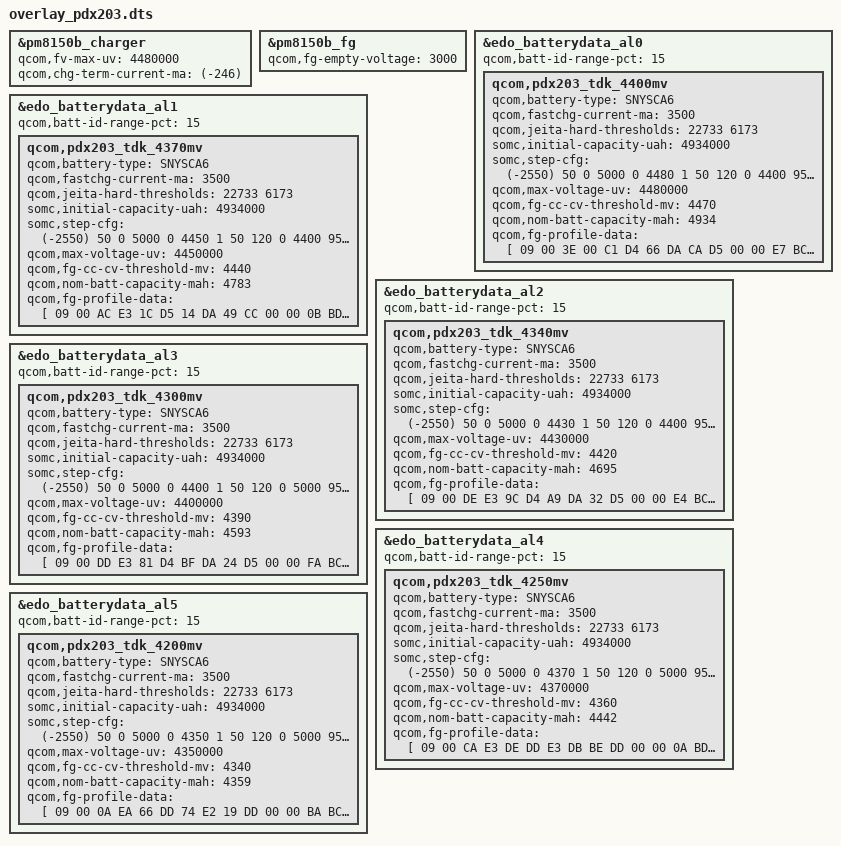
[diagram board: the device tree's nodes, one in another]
/dts-v1/;
/plugin/;

&pm8150b_charger {
	qcom,fv-max-uv = <4480000>;
	qcom,chg-term-current-ma = <(-246)>;
};
&pm8150b_fg {
	qcom,fg-empty-voltage = <3000>;
};
&edo_batterydata_al0 {
	qcom,batt-id-range-pct = <15>;
	qcom,pdx203_tdk_4400mv {
		qcom,battery-type = "SNYSCA6";
		qcom,fastchg-current-ma = <3500>;
		qcom,jeita-hard-thresholds = <22733 6173>;
		somc,initial-capacity-uah = <4934000>;
		somc,step-cfg = <
			(-2550)  50    0 5000    0 4480 1
			    50  120    0 4400  950 4480 2
			    50  120 4400 5000  700 4480 2
			   120  150    0 4150 2450 4480 3
			   120  150 4150 4250 1950 4480 3
			   120  150 4250 4350 1450 4480 3
			   120  150 4350 5000  950 4480 3
			   150  200    0 4150 2950 4480 3
			   150  200 4150 4250 2450 4480 3
			   150  200 4250 4350 1950 4480 3
			   150  200 4350 5000 1450 4480 3
			   200  350    0 4250 3500 4480 3
			   200  350 4250 4300 3500 4480 3
			   200  350 4300 4400 2450 4480 3
			   200  350 4400 5000 1700 4480 3
			   350  450    0 4250 3500 4480 3
			   350  450 4250 4300 3500 4480 3
			   350  450 4300 4400 2450 4480 3
			   350  450 4400 5000 1700 4480 3
			   450  550    0 5000 1450 4200 4
			   550 2550    0 5000    0 4200 5
		>;
		qcom,max-voltage-uv = <4480000>;
		qcom,fg-cc-cv-threshold-mv = <4470>;
		qcom,nom-batt-capacity-mah = <4934>;
		qcom,fg-profile-data = [
			 09 00 3E 00
			 C1 D4 66 DA
			 CA D5 00 00
			 E7 BC F7 8A
			 FB 87 94 8B
			 3F 9D 68 80
			 20 00 DB FA
			 48 13 D7 FD
			 0F E5 CE 07
			 32 00 5B 00
			 A3 ED 27 D3
			 84 0A 35 E5
			 49 C5 01 12
			 E3 01 A9 D2
			 60 00 4B 00
			 4C 00 48 00
			 28 00 2F 00
			 37 00 3C 00
			 40 00 41 00
			 40 00 60 00
			 35 00 41 00
			 48 00 44 00
			 3D 00 90 00
			 5F 64 4E 00
			 44 00 40 08
			 60 F8 4C 00
			 47 00 6C 10
			 55 10 48 00
			 99 28 69 48
			 56 60 4A 0C
			 48 00 D8 00
			 7B 1F BC 0D
			 2B 02 A7 05
			 80 1C 4A 0B
			 A3 0D 91 22
			 27 18 31 42
			 50 55 49 02
			 67 11 78 1F
			 CF 05 33 0A
			 AE 06 E2 1C
			 FC 01 B5 05
			 90 02 76 18
			 3F 23 0C 45
			 B1 53 77 11
			 4C 1F FD E5
			 1B C2 B8 96
			 DC 1C A2 B9
			 F2 04 8A BB
			 3A 18 48 93
			 16 85 8C 9B
			 80 98 09 80
			 BA EB BF 04
			 59 FC E2 03
			 00 00 83 DC
			 49 E2 F0 FF
			 23 BB 04 AD
			 18 10 19 F0
			 94 C5 93 03
			 17 05 9F 00
			 CE 07 32 00
			 6A 01 76 02
			 F8 05 1F 02
			 07 05 03 05
			 A0 03 86 02
			 14 04 44 00
			 3D 00 4C 00
			 50 64 54 00
			 52 00 52 08
			 54 F8 52 00
			 55 00 68 08
			 34 08 42 00
			 55 28 52 48
			 5E 58 6F 0D
			 48 00 59 00
			 5D 08 61 00
			 54 00 42 00
			 4B 08 56 08
			 4E 00 62 28
			 7A 48 46 60
			 59 0D 61 00
			 61 00 49 08
			 D8 F8 5D 20
			 57 05 52 0A
			 27 0D 09 1D
			 AB 22 A2 44
			 55 5B 94 18
			 11 02 A4 05
			 B7 03 78 0F
			 3F 0A 38 20
			 14 05 C2 02
			 1B 06 D9 1C
			 C7 02 55 04
			 E3 03 85 18
			 16 02 87 05
			 06 02 71 00
			 53 1F FF 05
			 2B 02 39 05
			 DB 1C 59 02
			 0F 05 4F 03
			 A7 18 67 03
			 9F 04 51 02
			 6D 00 0D 01
			 C0 00 FA 00
			 46 13 00 00
		];
	};
};
&edo_batterydata_al1 {
	qcom,batt-id-range-pct = <15>;
	qcom,pdx203_tdk_4370mv {
		qcom,battery-type = "SNYSCA6";
		qcom,fastchg-current-ma = <3500>;
		qcom,jeita-hard-thresholds = <22733 6173>;
		somc,initial-capacity-uah = <4934000>;
		somc,step-cfg = <
			(-2550)  50    0 5000    0 4450 1
			    50  120    0 4400  950 4450 2
			    50  120 4400 5000  700 4450 2
			   120  150    0 4150 2450 4450 3
			   120  150 4150 4250 1950 4450 3
			   120  150 4250 4350 1450 4450 3
			   120  150 4350 5000  950 4450 3
			   150  200    0 4150 2700 4450 3
			   150  200 4150 4250 2200 4450 3
			   150  200 4250 4350 1950 4450 3
			   150  200 4350 5000 1450 4450 3
			   200  350    0 4200 3500 4450 3
			   200  350 4200 4250 3400 4450 3
			   200  350 4250 4350 2200 4450 3
			   200  350 4350 5000 1450 4450 3
			   350  450    0 4200 3500 4450 3
			   350  450 4200 4250 3400 4450 3
			   350  450 4250 4350 2200 4450 3
			   350  450 4350 5000 1450 4450 3
			   450  550    0 5000 1450 4200 4
			   550 2550    0 5000    0 4200 5
		>;
		qcom,max-voltage-uv = <4450000>;
		qcom,fg-cc-cv-threshold-mv = <4440>;
		qcom,nom-batt-capacity-mah = <4783>;
		qcom,fg-profile-data = [
			 09 00 AC E3
			 1C D5 14 DA
			 49 CC 00 00
			 0B BD 1D 8B
			 F9 87 56 8A
			 74 9D 68 80
			 22 00 95 FA
			 1B 13 AA 06
			 1B E2 CE 07
			 32 00 F9 EA
			 86 ED 3B D3
			 8C 0A 42 E5
			 2D C5 B5 0B
			 A1 FB 54 D2
			 60 00 4D 00
			 4C 00 49 00
			 2E 00 2E 00
			 36 00 3B 00
			 41 00 41 00
			 40 00 60 00
			 34 00 41 00
			 49 00 45 00
			 3B 00 88 00
			 5C 64 4D 00
			 41 00 3F 08
			 60 F8 4D 00
			 48 00 67 10
			 56 10 45 00
			 A0 28 6D 48
			 56 60 48 0C
			 41 00 D8 00
			 9A 1F 8F 0D
			 4E 02 43 05
			 6F 1C 78 03
			 7C 05 B3 22
			 E3 17 4B 42
			 31 55 63 02
			 67 11 14 21
			 21 04 51 0B
			 AA FD F5 1C
			 A0 01 DD 04
			 74 03 6B 18
			 37 23 25 45
			 79 53 90 12
			 3C 1F 0D E6
			 0D C2 71 B5
			 D6 1C AD C1
			 CA 04 A2 BB
			 7D 18 ED 92
			 8D 85 D2 A2
			 7F A0 09 80
			 8C EB 6C 04
			 55 05 04 03
			 00 00 CC D4
			 22 EA F1 07
			 68 E2 C1 CD
			 17 18 1A 00
			 11 E5 23 03
			 7D 06 AE 00
			 CE 07 32 00
			 8C 01 AC 03
			 F3 05 46 01
			 31 04 5E 02
			 44 02 E8 02
			 6D 05 42 00
			 3C 00 4D 00
			 50 64 55 00
			 54 00 50 08
			 56 00 53 00
			 54 00 55 10
			 36 10 42 00
			 56 28 51 48
			 5F 60 70 0C
			 48 00 57 00
			 65 08 6B 00
			 50 00 43 00
			 4B 08 58 08
			 4F 00 61 28
			 7D 48 47 58
			 55 0D 61 00
			 5F 00 42 08
			 D8 F8 E6 1F
			 CE 05 05 0A
			 C9 0E D5 1C
			 54 23 B1 45
			 5B 5A 69 18
			 51 02 09 05
			 A0 02 6A 10
			 3F 0A BF 20
			 79 04 2F 03
			 AD 05 DB 1C
			 AD 02 98 04
			 81 03 8A 18
			 01 02 B7 05
			 99 03 78 00
			 C2 1F 7C 05
			 8A 02 6B 04
			 DE 1C 35 02
			 65 05 D8 02
			 A9 18 4C 03
			 D3 04 1C 02
			 75 00 05 01
			 C0 00 FA 00
			 AF 12 00 00
		];
	};
};
&edo_batterydata_al2 {
	qcom,batt-id-range-pct = <15>;
	qcom,pdx203_tdk_4340mv {
		qcom,battery-type = "SNYSCA6";
		qcom,fastchg-current-ma = <3500>;
		qcom,jeita-hard-thresholds = <22733 6173>;
		somc,initial-capacity-uah = <4934000>;
		somc,step-cfg = <
			(-2550)  50    0 5000    0 4430 1
			    50  120    0 4400  950 4430 2
			    50  120 4400 5000  700 4430 2
			   120  150    0 4150 2200 4430 3
			   120  150 4150 4250 1700 4430 3
			   120  150 4250 4350 1450 4430 3
			   120  150 4350 5000  950 4430 3
			   150  200    0 4150 2700 4430 3
			   150  200 4150 4250 2200 4430 3
			   150  200 4250 4350 1950 4430 3
			   150  200 4350 5000 1200 4430 3
			   200  350    0 4200 3500 4430 3
			   200  350 4200 4250 3400 4430 3
			   200  350 4250 4350 2200 4430 3
			   200  350 4350 5000 1450 4430 3
			   350  450    0 4200 3500 4430 3
			   350  450 4200 4250 3400 4430 3
			   350  450 4250 4350 2200 4430 3
			   350  450 4350 5000 1450 4430 3
			   450  550    0 5000 1450 4200 4
			   550 2550    0 5000    0 4200 5
		>;
		qcom,max-voltage-uv = <4430000>;
		qcom,fg-cc-cv-threshold-mv = <4420>;
		qcom,nom-batt-capacity-mah = <4695>;
		qcom,fg-profile-data = [
			 09 00 DE E3
			 9C D4 A9 DA
			 32 D5 00 00
			 E4 BC 12 8B
			 FA 87 89 80
			 51 8D 45 80
			 23 00 B9 01
			 EE 12 27 FD
			 3C E2 CE 07
			 32 00 63 00
			 59 ED AB D2
			 91 0A 36 E5
			 3B C5 DC 0B
			 E1 FB 03 D2
			 60 00 4C 00
			 4E 00 49 00
			 33 00 2F 00
			 37 00 3E 00
			 48 00 43 00
			 41 00 60 00
			 34 00 43 00
			 46 00 45 00
			 3A 00 7B 00
			 5C 64 4D 00
			 41 00 3C 08
			 60 00 51 00
			 4C 00 65 10
			 5B 10 47 00
			 A2 28 76 48
			 59 58 4B 0D
			 45 00 D8 00
			 A7 1F 8B 0D
			 45 02 A6 FE
			 8A 1C 1B 03
			 D3 05 4B 22
			 26 18 0D 42
			 AC 55 A9 03
			 6B 11 18 21
			 2A FC 3B 03
			 BF FD F9 1C
			 35 FB E2 04
			 5C 03 B1 18
			 0A 23 4E 45
			 47 53 91 12
			 35 1F 45 E4
			 D6 C3 B3 BD
			 DD 1C 31 C3
			 05 05 53 BB
			 5C 18 05 93
			 77 85 EB 9A
			 82 98 09 80
			 B4 DB 2D 05
			 71 FD BB F2
			 00 F8 7D DC
			 60 E2 EF FF
			 93 DB 9F BC
			 19 10 19 F0
			 6A D5 98 03
			 D1 04 42 03
			 CE 07 32 00
			 03 03 5E 03
			 05 05 D3 03
			 93 05 5D 03
			 33 03 7B 03
			 37 04 44 00
			 3B 00 4E 00
			 51 64 56 00
			 54 00 53 00
			 54 00 53 00
			 54 00 48 08
			 35 08 42 00
			 56 28 53 48
			 60 58 6F 0D
			 4B 00 55 00
			 61 08 64 00
			 50 00 3E 00
			 49 10 57 10
			 50 00 5E 28
			 7B 48 4B 58
			 51 0D 60 00
			 63 00 48 08
			 D8 00 0F 20
			 BE FD EE 0B
			 DE 0E F7 1C
			 D1 22 6A 44
			 7C 53 91 18
			 0C 02 AC 05
			 AB 03 75 10
			 3F 0A E3 1F
			 7D 05 65 02
			 65 06 BD 1C
			 1D 03 D9 05
			 42 02 80 18
			 0E 02 94 05
			 F4 03 6B 00
			 5F 20 E3 04
			 DF 02 EF 05
			 E9 1C FD 03
			 D7 05 45 02
			 AF 18 33 03
			 01 05 DC 03
			 82 00 0D 01
			 C0 00 FA 00
			 57 12 00 00
		];
	};
};
&edo_batterydata_al3 {
	qcom,batt-id-range-pct = <15>;
	qcom,pdx203_tdk_4300mv {
		qcom,battery-type = "SNYSCA6";
		qcom,fastchg-current-ma = <3500>;
		qcom,jeita-hard-thresholds = <22733 6173>;
		somc,initial-capacity-uah = <4934000>;
		somc,step-cfg = <
			(-2550)  50    0 5000    0 4400 1
			    50  120    0 5000  950 4400 2
			   120  150    0 4150 1950 4400 3
			   120  150 4150 4250 1450 4400 3
			   120  150 4250 5000  950 4400 3
			   150  200    0 4100 2450 4400 3
			   150  200 4100 4200 1950 4400 3
			   150  200 4200 4300 1700 4400 3
			   150  200 4300 5000  950 4400 3
			   200  350    0 4150 3500 4400 3
			   200  350 4150 4200 2950 4400 3
			   200  350 4200 4300 1700 4400 3
			   200  350 4300 5000 1200 4400 3
			   350  450    0 4150 3500 4400 3
			   350  450 4150 4200 2950 4400 3
			   350  450 4200 4300 1700 4400 3
			   350  450 4300 5000 1200 4400 3
			   450  550    0 5000 1450 4200 4
			   550 2550    0 5000    0 4200 5
		>;
		qcom,max-voltage-uv = <4400000>;
		qcom,fg-cc-cv-threshold-mv = <4390>;
		qcom,nom-batt-capacity-mah = <4593>;
		qcom,fg-profile-data = [
			 09 00 DD E3
			 81 D4 BF DA
			 24 D5 00 00
			 FA BC DA 8A
			 FC 87 2B 82
			 CB 9D 7B 80
			 20 00 77 FB
			 EE 12 E6 06
			 D5 E4 CE 07
			 32 00 66 00
			 42 ED 93 D3
			 B5 0A 66 E5
			 1E C5 B6 0A
			 97 01 64 CB
			 60 00 4D 00
			 4D 00 4A 00
			 37 00 2D 00
			 36 00 41 00
			 4E 00 41 00
			 3E 00 60 00
			 36 00 44 00
			 48 00 49 00
			 3D 00 5C 00
			 64 64 52 00
			 42 00 3D 08
			 60 F8 50 00
			 4C 00 57 08
			 5D 08 49 00
			 71 20 70 40
			 58 58 4A 0E
			 44 00 D8 08
			 26 20 13 0D
			 84 02 DB FC
			 8E 1C DE 02
			 48 04 AF 23
			 4E 18 B3 43
			 17 54 DC 02
			 77 13 15 22
			 A0 05 BC 0B
			 54 05 F4 1C
			 1F FB 1B 05
			 FF 02 A8 18
			 D0 22 B5 45
			 92 52 9C 13
			 1B 21 46 E4
			 0D C3 E4 AD
			 E2 1C CF C2
			 CA 05 61 BA
			 4E 18 FB 92
			 8F 85 BD 9A
			 9E 98 09 80
			 B7 E3 D4 04
			 46 FC 2A F2
			 00 00 93 DC
			 3E E2 F0 07
			 E1 EA FE D4
			 27 10 19 00
			 B2 E5 9D 03
			 0D 05 7D 02
			 CE 07 32 00
			 99 01 D6 03
			 1B 04 48 02
			 89 05 11 02
			 E2 02 93 02
			 92 04 44 00
			 3B 00 4D 00
			 4F 64 53 00
			 53 F8 4F 00
			 51 F0 53 00
			 52 00 50 08
			 33 08 40 00
			 54 28 51 48
			 5B 58 6A 0D
			 5A 00 4B 00
			 56 08 61 F8
			 4C 00 41 00
			 47 08 55 08
			 52 00 5B 20
			 76 40 64 58
			 4C 0E 5D 00
			 63 00 44 08
			 D8 00 A8 1F
			 81 04 13 0B
			 E9 0C E5 1C
			 F2 22 39 44
			 A1 53 89 18
			 08 02 B1 05
			 A2 03 71 10
			 3F 0A 41 20
			 22 05 95 02
			 69 04 D1 1C
			 BF 02 77 04
			 8C 03 A1 18
			 A4 03 26 04
			 D2 02 75 00
			 7D 1F E2 05
			 1C 02 9B 06
			 CC 1C 5D 02
			 25 05 F9 02
			 AF 18 23 03
			 15 05 C1 03
			 73 00 0E 01
			 C0 00 FA 00
			 F1 11 00 00
		];
	};
};
&edo_batterydata_al4 {
	qcom,batt-id-range-pct = <15>;
	qcom,pdx203_tdk_4250mv {
		qcom,battery-type = "SNYSCA6";
		qcom,fastchg-current-ma = <3500>;
		qcom,jeita-hard-thresholds = <22733 6173>;
		somc,initial-capacity-uah = <4934000>;
		somc,step-cfg = <
			(-2550)  50    0 5000    0 4370 1
			    50  120    0 5000  950 4370 2
			   120  150    0 4150 1950 4370 3
			   120  150 4150 4250 1450 4370 3
			   120  150 4250 5000  950 4370 3
			   150  200    0 4100 2450 4370 3
			   150  200 4100 4200 1950 4370 3
			   150  200 4200 4300 1700 4370 3
			   150  200 4300 5000  950 4370 3
			   200  350    0 4150 3500 4370 3
			   200  350 4150 4200 2950 4370 3
			   200  350 4200 4300 1700 4370 3
			   200  350 4300 5000 1200 4370 3
			   350  450    0 4150 3500 4370 3
			   350  450 4150 4200 2950 4370 3
			   350  450 4200 4300 1700 4370 3
			   350  450 4300 5000 1200 4370 3
			   450  550    0 5000 1450 4200 4
			   550 2550    0 5000    0 4200 5
		>;
		qcom,max-voltage-uv = <4370000>;
		qcom,fg-cc-cv-threshold-mv = <4360>;
		qcom,nom-batt-capacity-mah = <4442>;
		qcom,fg-profile-data = [
			 09 00 CA E3
			 DE DD E3 DB
			 BE DD 00 00
			 0A BD 04 8B
			 F9 87 A7 8C
			 92 8C 75 80
			 27 00 EF FB
			 98 12 12 06
			 AB F2 CE 07
			 32 00 13 F2
			 CE EC 43 B2
			 66 0B 9A E5
			 5D C4 CC 03
			 63 FB CE CA
			 60 00 46 00
			 45 00 43 00
			 42 00 26 00
			 35 00 46 00
			 3E 00 43 00
			 44 00 60 00
			 29 00 35 00
			 3F 00 42 00
			 37 00 38 00
			 59 64 43 00
			 3B 00 33 08
			 60 00 50 00
			 4D 00 47 10
			 65 10 49 00
			 4B 20 73 48
			 56 58 48 0D
			 41 00 D8 00
			 24 20 21 0D
			 63 02 88 06
			 69 1C 33 03
			 E7 05 04 22
			 3A 18 EC 43
			 C8 55 7D 03
			 76 12 54 20
			 14 05 74 0A
			 67 06 E7 1C
			 BD 01 6F 04
			 87 03 8C 18
			 F0 22 8B 45
			 D3 52 8D 13
			 2A 20 43 E5
			 55 C2 7B BE
			 DB 1C 7C B1
			 7B 05 8E BA
			 80 18 C7 92
			 CB 85 69 9A
			 96 98 09 80
			 99 DB 77 04
			 6A 02 A6 02
			 00 F8 B3 E4
			 3B EA F0 07
			 4B 02 1E A5
			 38 08 1A D8
			 1A DA BA 03
			 64 06 CA 00
			 CE 07 32 00
			 49 03 4F 02
			 71 05 6C 02
			 33 00 F2 03
			 47 03 E5 04
			 EE 05 44 00
			 3A 00 4D 00
			 4F 64 53 00
			 55 00 50 00
			 51 E0 52 00
			 52 00 43 08
			 33 08 3F 00
			 54 28 52 48
			 5B 58 67 0D
			 6F 00 48 00
			 5A 08 65 00
			 52 00 3F 00
			 45 08 54 08
			 54 00 57 20
			 72 40 74 58
			 46 0F 59 00
			 60 00 4F 08
			 D8 00 45 1F
			 DA 06 EF 01
			 9C 04 DF 1C
			 E9 22 65 44
			 56 53 83 18
			 08 02 B1 05
			 A2 03 71 12
			 3F 0A 3D 21
			 2B 04 22 03
			 B9 05 E0 1C
			 73 02 1D 05
			 B6 02 AE 18
			 67 03 A0 04
			 50 02 85 00
			 48 21 20 04
			 2A 03 B4 05
			 EC 1C D6 01
			 58 04 85 03
			 C1 18 E5 02
			 85 05 EF 02
			 92 00 0E 01
			 C0 00 FA 00
			 5A 11 00 00
		];
	};
};
&edo_batterydata_al5 {
	qcom,batt-id-range-pct = <15>;
	qcom,pdx203_tdk_4200mv {
		qcom,battery-type = "SNYSCA6";
		qcom,fastchg-current-ma = <3500>;
		qcom,jeita-hard-thresholds = <22733 6173>;
		somc,initial-capacity-uah = <4934000>;
		somc,step-cfg = <
			(-2550)  50    0 5000    0 4350 1
			    50  120    0 5000  950 4350 2
			   120  150    0 4150 1950 4350 3
			   120  150 4150 4250 1450 4350 3
			   120  150 4250 5000  950 4350 3
			   150  200    0 4100 2450 4350 3
			   150  200 4100 4200 1950 4350 3
			   150  200 4200 4300 1700 4350 3
			   150  200 4300 5000  950 4350 3
			   200  350    0 4150 3500 4350 3
			   200  350 4150 4200 2950 4350 3
			   200  350 4200 4300 1700 4350 3
			   200  350 4300 5000 1200 4350 3
			   350  450    0 4150 3500 4350 3
			   350  450 4150 4200 2950 4350 3
			   350  450 4200 4300 1700 4350 3
			   350  450 4300 5000 1200 4350 3
			   450  550    0 5000 1450 4200 4
			   550 2550    0 5000    0 4200 5
		>;
		qcom,max-voltage-uv = <4350000>;
		qcom,fg-cc-cv-threshold-mv = <4340>;
		qcom,nom-batt-capacity-mah = <4359>;
		qcom,fg-profile-data = [
			 09 00 0A EA
			 66 DD 74 E2
			 19 DD 00 00
			 BA BC 05 8B
			 FB 87 C8 9D
			 73 87 86 80
			 25 00 04 02
			 A3 12 BF FC
			 8D EA CE 07
			 32 00 2F F2
			 8A EC 20 C5
			 36 0B 01 DD
			 C7 C4 05 0A
			 84 01 6C C3
			 60 00 45 00
			 45 00 44 00
			 44 00 2A 00
			 33 00 3F 00
			 3B 00 45 00
			 2C 00 60 00
			 29 00 35 00
			 40 00 43 00
			 3A 00 36 00
			 5E 64 42 00
			 3C 00 35 08
			 60 00 54 00
			 4E 00 48 08
			 6B 08 4E 00
			 47 20 7A 40
			 5A 58 49 0F
			 46 00 D8 00
			 A4 20 C7 0C
			 76 02 83 06
			 8C 1C A5 02
			 DC 04 D3 22
			 53 18 8C 43
			 60 54 91 02
			 86 13 6D 21
			 13 0C FD 0A
			 F5 05 E0 1C
			 B6 F9 AA 04
			 16 03 82 18
			 CC 22 C9 45
			 6B 52 9B 14
			 D8 22 64 E5
			 C8 C3 4B C5
			 DF 1C BD C2
			 DE 05 0D BA
			 5B 18 BB 92
			 EE 85 27 92
			 AE 80 09 80
			 E5 C3 4C 04
			 CF 03 B3 F5
			 00 00 13 EC
			 AD F2 EC 07
			 4C EC 38 B7
			 68 08 1A 00
			 0D E4 B3 03
			 58 06 72 03
			 CE 07 32 00
			 C5 01 62 03
			 A3 04 12 07
			 51 02 2D 04
			 C4 03 2E 02
			 37 04 49 00
			 3A 00 4F 00
			 51 64 56 00
			 59 E8 59 E8
			 57 F0 57 00
			 5C 00 53 08
			 33 08 3B 00
			 53 20 50 40
			 57 58 61 0F
			 70 00 47 00
			 53 08 66 F8
			 69 00 3C 00
			 41 08 52 08
			 59 00 53 20
			 6A 40 7B 58
			 45 0F 53 00
			 6A 00 5E 08
			 D8 F8 30 1E
			 6A 02 15 0C
			 A9 0B EA 1C
			 A2 22 EB 44
			 C4 52 92 18
			 A4 03 46 04
			 A4 02 69 12
			 3F 0A CF 20
			 C1 04 9C 02
			 61 04 CE 1C
			 8E 02 01 05
			 B5 02 A1 18
			 65 03 A4 04
			 4D 02 84 00
			 E7 1F 9E 05
			 12 02 49 05
			 D6 1C 10 02
			 C7 05 16 02
			 C4 18 C5 02
			 B4 05 A3 02
			 84 00 14 01
			 C0 00 FA 00
			 07 11 00 00
		];
	};
};
